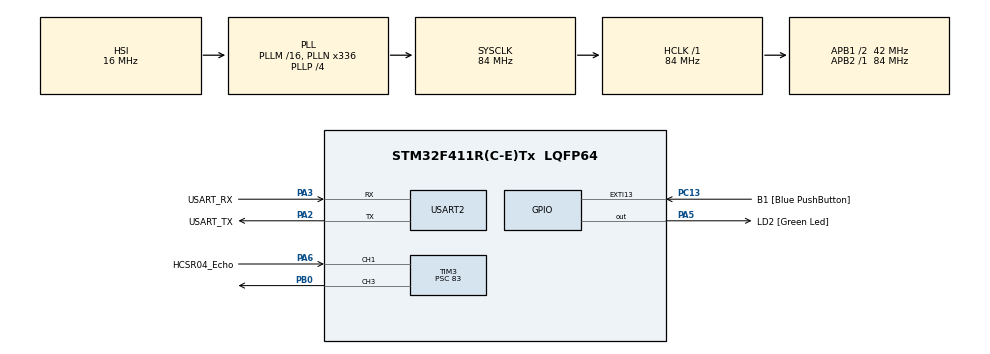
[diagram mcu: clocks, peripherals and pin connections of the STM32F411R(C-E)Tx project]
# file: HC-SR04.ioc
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Mcu.Family=STM32F4
Mcu.Name=STM32F411R(C-E)Tx
Mcu.Package=LQFP64
NVIC.PriorityGroup=NVIC_PRIORITYGROUP_0
NVIC.TIM3_IRQn=true\:0\:0\:false\:true\:true\:1\:true\:true\:true
PA13.GPIO_Label=TMS
PA13.Mode=Serial_Wire
PA13.Signal=SYS_JTMS-SWDIO
PA14.GPIO_Label=TCK
PA14.Mode=Serial_Wire
PA14.Signal=SYS_JTCK-SWCLK
PA2.GPIO_Label=USART_TX
PA2.Mode=Asynchronous
PA2.Signal=USART2_TX
PA3.GPIO_Label=USART_RX
PA3.Mode=Asynchronous
PA3.Signal=USART2_RX
PA5.GPIO_Label=LD2 [Green Led]
PA5.Signal=GPIO_Output
PA6.GPIO_Label=HCSR04_Echo
PA6.Signal=S_TIM3_CH1
PB0.Signal=S_TIM3_CH3
PB3.GPIO_Label=SWO
PB3.Signal=SYS_JTDO-SWO
PC13-ANTI_TAMP.GPIO_Label=B1 [Blue PushButton]
PC13-ANTI_TAMP.GPIO_ModeDefaultEXTI=GPIO_MODE_IT_FALLING
PC13-ANTI_TAMP.Signal=GPXTI13
PC14-OSC32_IN.Mode=LSE-External-Oscillator
PC14-OSC32_IN.Signal=RCC_OSC32_IN
PC15-OSC32_OUT.Mode=LSE-External-Oscillator
PC15-OSC32_OUT.Signal=RCC_OSC32_OUT
PH0\ -\ OSC_IN.Mode=HSE-External-Clock-Source
PH0\ -\ OSC_IN.Signal=RCC_OSC_IN
PH1\ -\ OSC_OUT.Mode=HSE-External-Clock-Source
PH1\ -\ OSC_OUT.Signal=RCC_OSC_OUT
ProjectManager.HeapSize=0x200
ProjectManager.StackSize=0x400
ProjectManager.TargetToolchain=STM32CubeIDE
RCC.48MHZClocksFreq_Value=84000000
RCC.AHBFreq_Value=84000000
RCC.APB1CLKDivider=RCC_HCLK_DIV2
RCC.APB1Freq_Value=42000000
RCC.APB1TimFreq_Value=84000000
RCC.APB2Freq_Value=84000000
RCC.APB2TimFreq_Value=84000000
RCC.CortexFreq_Value=84000000
RCC.FLatency-AdvancedSettings=FLASH_LATENCY_2
RCC.HCLKFreq_Value=84000000
RCC.HSE_VALUE=8000000
RCC.HSI_VALUE=16000000
RCC.PLLN=336
RCC.PLLP=RCC_PLLP_DIV4
RCC.SYSCLKFreq_VALUE=84000000
RCC.SYSCLKSource=RCC_SYSCLKSOURCE_PLLCLK
RCC.VCOOutputFreq_Value=336000000
SH.S_TIM3_CH1.0=TIM3_CH1,Input_Capture1_from_TI1
SH.S_TIM3_CH3.0=TIM3_CH3,PWM Generation3 CH3
TIM3.Channel-Input_Capture1_from_TI1=TIM_CHANNEL_1
TIM3.Channel-Input_Capture2_from_TI1_63=TIM_CHANNEL_2
TIM3.Channel-PWM\ Generation3\ CH3=TIM_CHANNEL_3
TIM3.ICPolarity_CH2=TIM_INPUTCHANNELPOLARITY_FALLING
TIM3.Prescaler=83
TIM3.Pulse-PWM\ Generation3\ CH3=11
USART2.VirtualMode=VM_ASYNC
VP_TIM3_VS_ClockSourceINT.Mode=Internal
VP_TIM3_VS_indirect_ch1.Mode=Input_Capture2_from_TI1_63
board=NUCLEO-F411RE

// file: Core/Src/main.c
/* USER CODE BEGIN Header */
/**
  ******************************************************************************
  * @file           : main.c
  * @brief          : Main program body
  ******************************************************************************
  * @attention
  *
  * Copyright (c) 2023 STMicroelectronics.
  * All rights reserved.
  *
  * This software is licensed under terms that can be found in the LICENSE file
  * in the root directory of this software component.
  * If no LICENSE file comes with this software, it is provided AS-IS.
  *
  ******************************************************************************
  */
/* USER CODE END Header */
#include "main.h"
#include "tim.h"
#include "usart.h"
#include "gpio.h"

/* USER CODE BEGIN Includes */
#include "hcsr04.h"
/* USER CODE END Includes */

/* USER CODE BEGIN PV */
HCSR04_t HCSR04;

float Result_HCSR04_f;
uint16_t Result_HCSR04_u16;
/* USER CODE END PV */

void SystemClock_Config(void);
static void MX_NVIC_Init(void);

int main(void)
{

  /* MCU Configuration--------------------------------------------------------*/

  /* Reset of all peripherals, Initializes the Flash interface and the Systick. */
  HAL_Init();

  /* Configure the system clock */
  SystemClock_Config();

  /* Initialize all configured peripherals */
  MX_GPIO_Init();
  MX_USART2_UART_Init();
  MX_TIM3_Init();

  /* Initialize interrupts */
  MX_NVIC_Init();
  /* USER CODE BEGIN 2 */
  HCSR04Init(&HCSR04,&htim3,&htim3,TIM_CHANNEL_3,TIM_CHANNEL_1,TIM_CHANNEL_2);

  /* USER CODE END 2 */

  /* Infinite loop */
  /* USER CODE BEGIN WHILE */
  while (1)
  {
	  //HCSR04StartMeasure(&HCSR04);
      //HCSR04WaitForResponse (&HCSR04);
	  HCSR04CalculateResultFloat (&HCSR04, &Result_HCSR04_f);
	  HCSR04CalculateResultIntiger(&HCSR04,&Result_HCSR04_u16);
	  HAL_Delay(100);
    /* USER CODE END WHILE */

  }
}

void SystemClock_Config(void)
{
  RCC_OscInitTypeDef RCC_OscInitStruct = {0};
  RCC_ClkInitTypeDef RCC_ClkInitStruct = {0};

  /** Configure the main internal regulator output voltage
  */
  __HAL_RCC_PWR_CLK_ENABLE();
  __HAL_PWR_VOLTAGESCALING_CONFIG(PWR_REGULATOR_VOLTAGE_SCALE1);

  /** Initializes the RCC Oscillators according to the specified parameters
  * in the RCC_OscInitTypeDef structure.
  */
  RCC_OscInitStruct.OscillatorType = RCC_OSCILLATORTYPE_HSI;
  RCC_OscInitStruct.HSIState = RCC_HSI_ON;
  RCC_OscInitStruct.HSICalibrationValue = RCC_HSICALIBRATION_DEFAULT;
  RCC_OscInitStruct.PLL.PLLState = RCC_PLL_ON;
  RCC_OscInitStruct.PLL.PLLSource = RCC_PLLSOURCE_HSI;
  RCC_OscInitStruct.PLL.PLLM = 16;
  RCC_OscInitStruct.PLL.PLLN = 336;
  RCC_OscInitStruct.PLL.PLLP = RCC_PLLP_DIV4;
  RCC_OscInitStruct.PLL.PLLQ = 4;
  if (HAL_RCC_OscConfig(&RCC_OscInitStruct) != HAL_OK)
  {
    Error_Handler();
  }

  /** Initializes the CPU, AHB and APB buses clocks
  */
  RCC_ClkInitStruct.ClockType = RCC_CLOCKTYPE_HCLK|RCC_CLOCKTYPE_SYSCLK
                              |RCC_CLOCKTYPE_PCLK1|RCC_CLOCKTYPE_PCLK2;
  RCC_ClkInitStruct.SYSCLKSource = RCC_SYSCLKSOURCE_PLLCLK;
  RCC_ClkInitStruct.AHBCLKDivider = RCC_SYSCLK_DIV1;
  RCC_ClkInitStruct.APB1CLKDivider = RCC_HCLK_DIV2;
  RCC_ClkInitStruct.APB2CLKDivider = RCC_HCLK_DIV1;

  if (HAL_RCC_ClockConfig(&RCC_ClkInitStruct, FLASH_LATENCY_2) != HAL_OK)
  {
    Error_Handler();
  }
}

/**
  * @brief NVIC Configuration.
  * @retval None
  */
static void MX_NVIC_Init(void)
{
  /* TIM3_IRQn interrupt configuration */
  HAL_NVIC_SetPriority(TIM3_IRQn, 0, 0);
  HAL_NVIC_EnableIRQ(TIM3_IRQn);
}

/* USER CODE BEGIN 4 */
void HAL_TIM_IC_CaptureCallback(TIM_HandleTypeDef *htim)
{
	if(htim== HCSR04.htim_echo)
	{
		HCSR04_InterruptHandler(&HCSR04);

	}
}
/* USER CODE END 4 */

void Error_Handler(void)
{
  __disable_irq();
  while (1)
  {
  }
}
